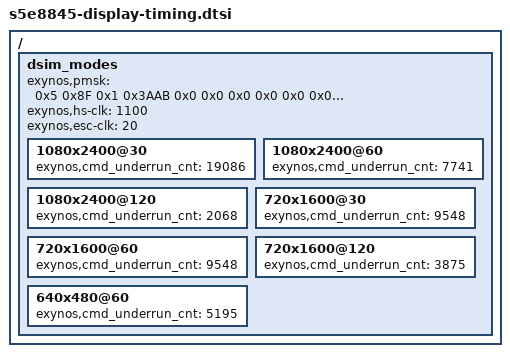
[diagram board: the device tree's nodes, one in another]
// SPDX-License-Identifier: GPL-2.0-only
/*
 * SAMSUNG EXYNOS SoC device tree source
 *
 * Copyright (c) 2019 Samsung Electronics Co., Ltd.
 *		http://www.samsung.com
 *
 */

/ {
	dsim_modes: dsim_modes {
		/*
		 * exynos,property can be declared in both dsim_modes node and
		 * the below nodes. The exynos,property of parent node is inherited to
		 * child node only if child node don't have exynos,property.
		 */
		exynos,pmsk = <
			0x5 0x8F 0x1 0x3AAB	/* p m s k */
			0x0 0x0 0x0 0x0		/* mfr mrr sel_pf icp */
			0x0 0x0 0x0 0x0		/* afc_enb extafc feed_en fsel */
			0x0 0x0			/* fout_mask rsel */
			>;
		exynos,hs-clk = <1100>;
		exynos,esc-clk = <20>;
		1080x2400@30 {
		        exynos,cmd_underrun_cnt = <19086>;
		};
		1080x2400@60 {
		        exynos,cmd_underrun_cnt = <7741>;
		};
		1080x2400@120 {
		        exynos,cmd_underrun_cnt = <2068>;
		};
		720x1600@30 {
		        exynos,cmd_underrun_cnt = <9548>;
		};
		720x1600@60 {
		        exynos,cmd_underrun_cnt = <9548>;
		};
		720x1600@120 {
		        exynos,cmd_underrun_cnt = <3875>;
		};
		/* for zebu emulator */
		640x480@60 {
		        exynos,cmd_underrun_cnt = <5195>;
		};
	};
};
